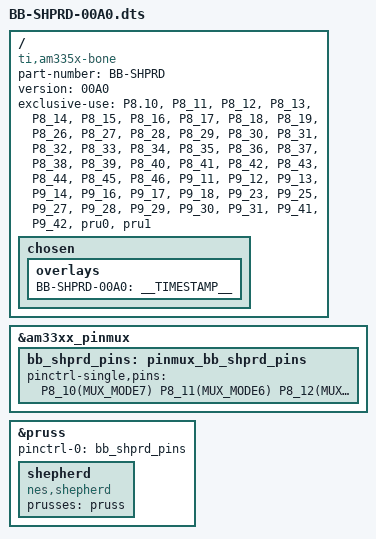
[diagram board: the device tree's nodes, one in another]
/dts-v1/;
/plugin/;
#include "am335x_pinctrl.h"

/*
// future-reference, gpio.h contains: BONE_P8_03, etc
#include <dt-bindings/gpio/gpio.h>
// future-reference, omap.h contains: MUX_MODE#, PULL_UP, INPUT_EN, AM33XX_IOPAD, AM33XX_PADCONF, etc
#include <dt-bindings/pinctrl/omap.h>
*/


/ {
   // note: (older) "ti,beaglebone" types seem to be working as well for v4.19.x-ti, but this is more future-proof
   compatible = "ti,am335x-bone", "ti,am335x-bone-black", "ti,am335x-bone-green";

   part-number = "BB-SHPRD";
   version = "00A0";

   /* This overlay uses the following resources */
   exclusive-use =

        "P8.10", /*     WD ACK */
        "P8_11", /*     pru0_dbg_Led1 */
        "P8_12", /*     pru0_dbg_Led0 */
        "P8_13", /*     EN_Shepherd */
        "P8_14", /*     target_GPIO0 */
        "P8_15", /* 	target_GPIO3 */
        "P8_16", /* 	target_GPIO2 */
        "P8_17", /* 	target_GPIO1 */
        "P8_18", /* 	BTN Sense */
        "P8_19", /* 	BTN Led */

        "P8_26", /* 	target_GPIO4 */
        "P8_27", /* 	pru1_target_uart-tx */
        "P8_28", /* 	pru1_dbg_Led0 */
        "P8_29", /* 	pru1_target_batOK */
        "P8_30", /* 	pru1_dbg_Led1 */
        "P8_31", /* 	IO-Dir Program1 TDIO */
        "P8_32", /* 	IO-Dir Program2 TMS */
        "P8_33", /* 	target_swd2_io */
        "P8_34", /* 	target_GPIO6 */
        "P8_35", /*     target_swd2_CLK */
        "P8_36", /*     target_GPIO5 */
        "P8_37", /*     IO_DIR_GPIO 0to3 */
        "P8_38", /*     IO_DIR_UART-TX */
        "P8_39", /* 	pru1_target_gpio6 */
        "P8_40", /* 	pru1_target_uart-tx */
        "P8_41", /* 	pru1_target_gpio4 */
        "P8_42", /* 	pru1_target_gpio5 */
        "P8_43", /* 	pru1_target_gpio2 */
        "P8_44", /* 	pru1_target_gpio3 */
        "P8_45", /* 	pru1_target_gpio0 */
        "P8_46", /* 	pru1_target_gpio1 */

        "P9_11", /* 	target_io_SEL */
        "P9_12", /* 	target_io_EN */
        "P9_13", /* 	target_Pwr_SEL */
        "P9_14", /*     EN_Recorder */

        "P9_16", /*     EN_Emulator */
        "P9_17", /* 	target_swd1_clk */
        "P9_18", /* 	target_swd1_io */

        "P9_23", /* 	Mem_WP */

        "P9_25", /* 	pru0 SPI_CS_ADC2_REC */

        "P9_27", /* 	pru0 SPI_CS_DAC_REC */
        "P9_28", /* 	pru0 SPI_CS_DAC_EMU */
        "P9_29", /* 	pru0 SPI_MOSI */
        "P9_30", /* 	pru0 SPI_MISO */
        "P9_31", /* 	pru0 SPI_SCK */

        "P9_41", /* 	pru0 SPI_CS_ADC1_REC */
        "P9_42", /* 	pru0 SPI_CS_ADC_EMU */

        /* Realtime Units */
        "pru0",
        "pru1";

        // additional shepherd-pins (there are covered by bb-overlays)
        // GPS,
        //"P8.07", /*  GPS PPS */
        //"P8.08", /*  GPS nReset */
        //"P8.09", /*  GPS Safeboot */
        //"P9_21", /*  GPS UART2TX */  // UART2
        //"P9_22", /*  GPS UART2RX */

        // EEPROM
        //"P9_19", /*  Mem_SCL */      // I2C2
        //"P9_20", /*  Mem_SDA */

        // Target UART - TODO: only active for TESTs
        //"P9_24", /*  target_uart_tx */ // UART1
        //"P9_26", /*  target_uart_rx */

   /* Check Table 9-60 in am335x TRM */

   /* Helper to show loaded overlays under: /proc/device-tree/chosen/overlays/  */
   /* Note:
        - root-path and "chosen" seem to produce a warning with dtc, internet is not helpful
        - this is the reference solution choosen by: https://github.com/RobertCNelson/bb.org-overlays
   */
   fragment@0 {
      target-path="/";
      __overlay__ {
         chosen {
            overlays {
               BB-SHPRD-00A0 = __TIMESTAMP__;
            };
         };
      };
   };


   fragment@1 {
      target = <&am33xx_pinmux>;
      __overlay__ {
         bb_shprd_pins: pinmux_bb_shprd_pins {
            pinctrl-single,pins = <

            P8_10(MUX_MODE7)                // gpio2[4]
            P8_11(MUX_MODE6)                // pr1_pru0_pru_r30_15
            P8_12(MUX_MODE6)                // pr1_pru0_pru_r30_14
            P8_13(MUX_MODE7)                // gpio0[23]
            P8_14(MUX_MODE7 | RX_ACTIVE)    // gpio0[26]
            P8_15(MUX_MODE7 | RX_ACTIVE)    // gpio1[15]
            P8_16(MUX_MODE7 | RX_ACTIVE)    // gpio1[14]
            P8_17(MUX_MODE7 | RX_ACTIVE)    // gpio0[27]
            P8_18(MUX_MODE7 | RX_ACTIVE)    // gpio2[1]
            P8_19(MUX_MODE7)                // gpio0[22]

            P8_26(MUX_MODE7 | RX_ACTIVE)    // gpio1[29]
            P8_27(MUX_MODE6 | RX_ACTIVE)    // pr1_pru1_pru_r31_8
            P8_28(MUX_MODE5)                // pr1_pru1_pru_r30_10
            P8_29(MUX_MODE5)                // pr1_pru1_pru_r30_9   BATOK, only output
            P8_30(MUX_MODE5)                // pr1_pru1_pru_r30_11

            P8_31(MUX_MODE7)                // gpio0[10]
            P8_32(MUX_MODE7)                // gpio0[11]
            P8_33(MUX_MODE7 | RX_ACTIVE)    // gpio0[9]
            P8_34(MUX_MODE7 | RX_ACTIVE)    // gpio2[17]
            P8_35(MUX_MODE7 | RX_ACTIVE)    // gpio0[8], TODO: test with rx enabled, not needed for CLK, but debug
            P8_36(MUX_MODE7 | RX_ACTIVE)    // gpio2[16]
            P8_37(MUX_MODE7)                // gpio2[14]
            P8_38(MUX_MODE7)                // gpio2[15]

            P8_39(MUX_MODE6 | RX_ACTIVE)    // pr1_pru1_pru_r31_6
            P8_40(MUX_MODE6 | RX_ACTIVE)    // pr1_pru1_pru_r31_7
            P8_41(MUX_MODE6 | RX_ACTIVE)    // pr1_pru1_pru_r31_4
            P8_42(MUX_MODE6 | RX_ACTIVE)    // pr1_pru1_pru_r31_5
            P8_43(MUX_MODE6 | RX_ACTIVE)    // pr1_pru1_pru_r31_2
            P8_44(MUX_MODE6 | RX_ACTIVE)    // pr1_pru1_pru_r31_3
            P8_45(MUX_MODE6 | RX_ACTIVE)    // pr1_pru1_pru_r31_0
            P8_46(MUX_MODE6 | RX_ACTIVE)    // pr1_pru1_pru_r31_1

            P9_11(MUX_MODE7)                // gpio0[30]
            P9_12(MUX_MODE7)                // gpio1[28]
            P9_13(MUX_MODE7)                // gpio0[31]

            P9_14(MUX_MODE7)                // gpio1[18], 50
            P9_16(MUX_MODE7)                // gpio1[19], 51

            P9_17(MUX_MODE7 | RX_ACTIVE)    // gpio0[5], swd_clk, TODO: test with rx enabled, not needed for CLK, but debug
            P9_18(MUX_MODE7 | RX_ACTIVE)    // gpio0[4], swd_io

            P9_23(MUX_MODE7)                // gpio1[17]

            P9_25(MUX_MODE5)                // pr1_pru0_pru_r30_7

            P9_27(MUX_MODE5)                // pr1_pru0_pru_r30_5
            P9_28(MUX_MODE5)                // pr1_pru0_pru_r30_3
            P9_29(MUX_MODE5)                // pr1_pru0_pru_r30_1
            P9_30(MUX_MODE6 | RX_ACTIVE)    // pr1_pru0_pru_r31_2
            P9_31(MUX_MODE5)                // pr1_pru0_pru_r30_0

            P9_41B(MUX_MODE5)               // pr1_pru0_pru_r30_6
            P9_42B(MUX_MODE5)               // pr1_pru0_pru_r30_4

            // just for tests, does not hinder uart-module from loading
            //P9_24(MUX_MODE7 | RX_ACTIVE)    // usually uart1
            //P9_26(MUX_MODE7 | RX_ACTIVE)    // usually uart1

            >;
         };
      };
   };

   fragment@2 {
       target = <&pruss>;
       __overlay__ {
            status = "okay";
            pinctrl-names = "default";
            pinctrl-0 = <&bb_shprd_pins>;
            shepherd{
               compatible = "nes,shepherd";
               prusses = <&pruss>;
            };	
       };
   };

};
